# ESP32-P4-LP register map
Vendor: ESPRESSIF SYSTEMS (SHANGHAI) CO., LTD.; Series: ESP32 P-Series; File version: 3
CPU: RV32IMAC r0p0, little endian, no MPU, no FPU, 0 interrupt priority bits
Address unit: 32 bits
Registers are 32-bit, read-write, reset 0x0 unless marked. A register's access mark holds for its fields unless they carry their own. Offsets are from the block's base; [hi:lo] are bit positions.

## HP2LP_PERI_PMS
Base 0x5012E800
0x00 TEE_HP2LP_TEE_PMS_DATE
  [31:0] TEE_TEE_DATE
0x04 TEE_PMS_CLK_EN
  [0] TEE_REG_CLK_EN
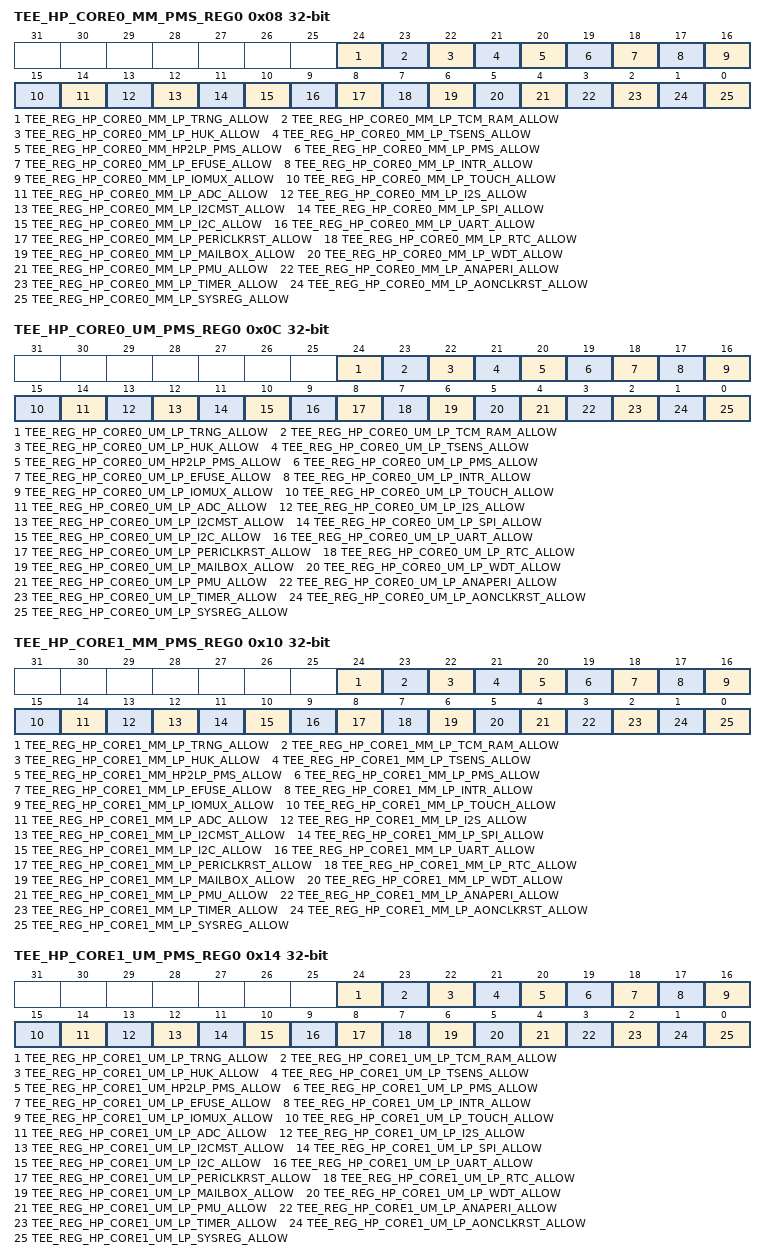
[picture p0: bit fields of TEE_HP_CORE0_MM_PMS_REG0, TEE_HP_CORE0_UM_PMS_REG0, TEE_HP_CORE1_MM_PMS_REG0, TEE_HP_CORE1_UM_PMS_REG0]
0x08 TEE_HP_CORE0_MM_PMS_REG0
  [24] TEE_REG_HP_CORE0_MM_LP_TRNG_ALLOW, [23] TEE_REG_HP_CORE0_MM_LP_TCM_RAM_ALLOW, [22] TEE_REG_HP_CORE0_MM_LP_HUK_ALLOW, [21] TEE_REG_HP_CORE0_MM_LP_TSENS_ALLOW, [20] TEE_REG_HP_CORE0_MM_HP2LP_PMS_ALLOW, [19] TEE_REG_HP_CORE0_MM_LP_PMS_ALLOW, [18] TEE_REG_HP_CORE0_MM_LP_EFUSE_ALLOW, [17] TEE_REG_HP_CORE0_MM_LP_INTR_ALLOW, [16] TEE_REG_HP_CORE0_MM_LP_IOMUX_ALLOW, [15] TEE_REG_HP_CORE0_MM_LP_TOUCH_ALLOW, [14] TEE_REG_HP_CORE0_MM_LP_ADC_ALLOW, [13] TEE_REG_HP_CORE0_MM_LP_I2S_ALLOW, [12] TEE_REG_HP_CORE0_MM_LP_I2CMST_ALLOW, [11] TEE_REG_HP_CORE0_MM_LP_SPI_ALLOW, [10] TEE_REG_HP_CORE0_MM_LP_I2C_ALLOW, [9] TEE_REG_HP_CORE0_MM_LP_UART_ALLOW, [8] TEE_REG_HP_CORE0_MM_LP_PERICLKRST_ALLOW, [7] TEE_REG_HP_CORE0_MM_LP_RTC_ALLOW, [6] TEE_REG_HP_CORE0_MM_LP_MAILBOX_ALLOW, [5] TEE_REG_HP_CORE0_MM_LP_WDT_ALLOW, [4] TEE_REG_HP_CORE0_MM_LP_PMU_ALLOW, [3] TEE_REG_HP_CORE0_MM_LP_ANAPERI_ALLOW, [2] TEE_REG_HP_CORE0_MM_LP_TIMER_ALLOW, [1] TEE_REG_HP_CORE0_MM_LP_AONCLKRST_ALLOW, [0] TEE_REG_HP_CORE0_MM_LP_SYSREG_ALLOW
0x0C TEE_HP_CORE0_UM_PMS_REG0
  [24] TEE_REG_HP_CORE0_UM_LP_TRNG_ALLOW, [23] TEE_REG_HP_CORE0_UM_LP_TCM_RAM_ALLOW, [22] TEE_REG_HP_CORE0_UM_LP_HUK_ALLOW, [21] TEE_REG_HP_CORE0_UM_LP_TSENS_ALLOW, [20] TEE_REG_HP_CORE0_UM_HP2LP_PMS_ALLOW, [19] TEE_REG_HP_CORE0_UM_LP_PMS_ALLOW, [18] TEE_REG_HP_CORE0_UM_LP_EFUSE_ALLOW, [17] TEE_REG_HP_CORE0_UM_LP_INTR_ALLOW, [16] TEE_REG_HP_CORE0_UM_LP_IOMUX_ALLOW, [15] TEE_REG_HP_CORE0_UM_LP_TOUCH_ALLOW, [14] TEE_REG_HP_CORE0_UM_LP_ADC_ALLOW, [13] TEE_REG_HP_CORE0_UM_LP_I2S_ALLOW, [12] TEE_REG_HP_CORE0_UM_LP_I2CMST_ALLOW, [11] TEE_REG_HP_CORE0_UM_LP_SPI_ALLOW, [10] TEE_REG_HP_CORE0_UM_LP_I2C_ALLOW, [9] TEE_REG_HP_CORE0_UM_LP_UART_ALLOW, [8] TEE_REG_HP_CORE0_UM_LP_PERICLKRST_ALLOW, [7] TEE_REG_HP_CORE0_UM_LP_RTC_ALLOW, [6] TEE_REG_HP_CORE0_UM_LP_MAILBOX_ALLOW, [5] TEE_REG_HP_CORE0_UM_LP_WDT_ALLOW, [4] TEE_REG_HP_CORE0_UM_LP_PMU_ALLOW, [3] TEE_REG_HP_CORE0_UM_LP_ANAPERI_ALLOW, [2] TEE_REG_HP_CORE0_UM_LP_TIMER_ALLOW, [1] TEE_REG_HP_CORE0_UM_LP_AONCLKRST_ALLOW, [0] TEE_REG_HP_CORE0_UM_LP_SYSREG_ALLOW
0x10 TEE_HP_CORE1_MM_PMS_REG0
  [24] TEE_REG_HP_CORE1_MM_LP_TRNG_ALLOW, [23] TEE_REG_HP_CORE1_MM_LP_TCM_RAM_ALLOW, [22] TEE_REG_HP_CORE1_MM_LP_HUK_ALLOW, [21] TEE_REG_HP_CORE1_MM_LP_TSENS_ALLOW, [20] TEE_REG_HP_CORE1_MM_HP2LP_PMS_ALLOW, [19] TEE_REG_HP_CORE1_MM_LP_PMS_ALLOW, [18] TEE_REG_HP_CORE1_MM_LP_EFUSE_ALLOW, [17] TEE_REG_HP_CORE1_MM_LP_INTR_ALLOW, [16] TEE_REG_HP_CORE1_MM_LP_IOMUX_ALLOW, [15] TEE_REG_HP_CORE1_MM_LP_TOUCH_ALLOW, [14] TEE_REG_HP_CORE1_MM_LP_ADC_ALLOW, [13] TEE_REG_HP_CORE1_MM_LP_I2S_ALLOW, [12] TEE_REG_HP_CORE1_MM_LP_I2CMST_ALLOW, [11] TEE_REG_HP_CORE1_MM_LP_SPI_ALLOW, [10] TEE_REG_HP_CORE1_MM_LP_I2C_ALLOW, [9] TEE_REG_HP_CORE1_MM_LP_UART_ALLOW, [8] TEE_REG_HP_CORE1_MM_LP_PERICLKRST_ALLOW, [7] TEE_REG_HP_CORE1_MM_LP_RTC_ALLOW, [6] TEE_REG_HP_CORE1_MM_LP_MAILBOX_ALLOW, [5] TEE_REG_HP_CORE1_MM_LP_WDT_ALLOW, [4] TEE_REG_HP_CORE1_MM_LP_PMU_ALLOW, [3] TEE_REG_HP_CORE1_MM_LP_ANAPERI_ALLOW, [2] TEE_REG_HP_CORE1_MM_LP_TIMER_ALLOW, [1] TEE_REG_HP_CORE1_MM_LP_AONCLKRST_ALLOW, [0] TEE_REG_HP_CORE1_MM_LP_SYSREG_ALLOW
0x14 TEE_HP_CORE1_UM_PMS_REG0
  [24] TEE_REG_HP_CORE1_UM_LP_TRNG_ALLOW, [23] TEE_REG_HP_CORE1_UM_LP_TCM_RAM_ALLOW, [22] TEE_REG_HP_CORE1_UM_LP_HUK_ALLOW, [21] TEE_REG_HP_CORE1_UM_LP_TSENS_ALLOW, [20] TEE_REG_HP_CORE1_UM_HP2LP_PMS_ALLOW, [19] TEE_REG_HP_CORE1_UM_LP_PMS_ALLOW, [18] TEE_REG_HP_CORE1_UM_LP_EFUSE_ALLOW, [17] TEE_REG_HP_CORE1_UM_LP_INTR_ALLOW, [16] TEE_REG_HP_CORE1_UM_LP_IOMUX_ALLOW, [15] TEE_REG_HP_CORE1_UM_LP_TOUCH_ALLOW, [14] TEE_REG_HP_CORE1_UM_LP_ADC_ALLOW, [13] TEE_REG_HP_CORE1_UM_LP_I2S_ALLOW, [12] TEE_REG_HP_CORE1_UM_LP_I2CMST_ALLOW, [11] TEE_REG_HP_CORE1_UM_LP_SPI_ALLOW, [10] TEE_REG_HP_CORE1_UM_LP_I2C_ALLOW, [9] TEE_REG_HP_CORE1_UM_LP_UART_ALLOW, [8] TEE_REG_HP_CORE1_UM_LP_PERICLKRST_ALLOW, [7] TEE_REG_HP_CORE1_UM_LP_RTC_ALLOW, [6] TEE_REG_HP_CORE1_UM_LP_MAILBOX_ALLOW, [5] TEE_REG_HP_CORE1_UM_LP_WDT_ALLOW, [4] TEE_REG_HP_CORE1_UM_LP_PMU_ALLOW, [3] TEE_REG_HP_CORE1_UM_LP_ANAPERI_ALLOW, [2] TEE_REG_HP_CORE1_UM_LP_TIMER_ALLOW, [1] TEE_REG_HP_CORE1_UM_LP_AONCLKRST_ALLOW, [0] TEE_REG_HP_CORE1_UM_LP_SYSREG_ALLOW
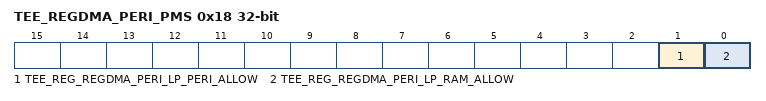
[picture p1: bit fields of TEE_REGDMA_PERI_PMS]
0x18 TEE_REGDMA_PERI_PMS
  [1] TEE_REG_REGDMA_PERI_LP_PERI_ALLOW, [0] TEE_REG_REGDMA_PERI_LP_RAM_ALLOW
